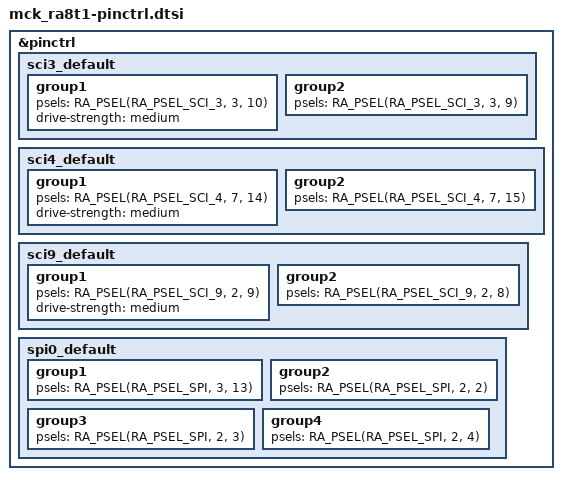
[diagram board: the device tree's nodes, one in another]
/*
 * Copyright (c) 2024 Renesas Electronics Corporation
 * SPDX-License-Identifier: Apache-2.0
 */

&pinctrl {
	status = "okay";

	sci3_default: sci3_default {
		group1 {
			/* tx */
			psels = <RA_PSEL(RA_PSEL_SCI_3, 3, 10)>;
			drive-strength = "medium";
		};
		group2 {
			/* rx */
			psels = <RA_PSEL(RA_PSEL_SCI_3, 3, 9)>;
		};
	};

	sci4_default: sci4_default {
		group1 {
			/* tx */
			psels = <RA_PSEL(RA_PSEL_SCI_4, 7, 14)>;
			drive-strength = "medium";
		};
		group2 {
			/* rx */
			psels = <RA_PSEL(RA_PSEL_SCI_4, 7, 15)>;
		};
	};

	sci9_default: sci9_default {
		group1 {
			/* tx */
			psels = <RA_PSEL(RA_PSEL_SCI_9, 2, 9)>;
			drive-strength = "medium";
		};
		group2 {
			/* rx */
			psels = <RA_PSEL(RA_PSEL_SCI_9, 2, 8)>;
		};
	};

	spi0_default: spi0_default {
		group1 {
			/* MISO */
			psels = <RA_PSEL(RA_PSEL_SPI, 3, 13)>;
		};
		group2 {
			/* MOSI */
			psels = <RA_PSEL(RA_PSEL_SPI, 2, 2)>;
		};
		group3 {
			/* RSPCK */
			psels = <RA_PSEL(RA_PSEL_SPI, 2, 3)>;
		};
		group4 {
			/* SSLB */
			psels = <RA_PSEL(RA_PSEL_SPI, 2, 4)>;
		};
	};
};
